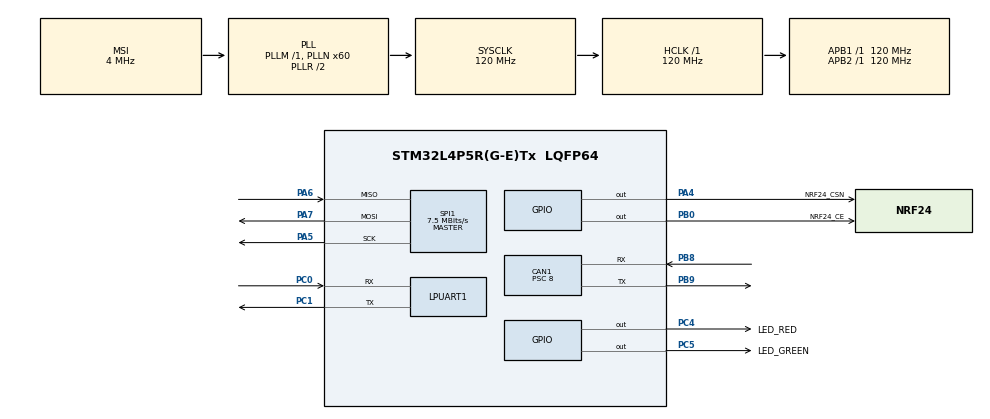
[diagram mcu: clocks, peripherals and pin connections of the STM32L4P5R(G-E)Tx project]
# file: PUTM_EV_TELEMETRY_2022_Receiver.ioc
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CAN1.BS1=CAN_BS1_12TQ
CAN1.BS2=CAN_BS2_2TQ
CAN1.CalculateBaudRate=999999
CAN1.CalculateTimeBit=1000
CAN1.CalculateTimeQuantum=66.66666666666667
CAN1.Mode=CAN_MODE_LOOPBACK
CAN1.Prescaler=8
CAN1.SJW=CAN_SJW_1TQ
Mcu.Family=STM32L4
Mcu.Name=STM32L4P5R(G-E)Tx
Mcu.Package=LQFP64
NVIC.CAN1_RX0_IRQn=true\:1\:0\:true\:false\:true\:true\:true\:true
NVIC.CAN1_RX1_IRQn=true\:0\:0\:false\:false\:true\:true\:true\:true
NVIC.PriorityGroup=NVIC_PRIORITYGROUP_4
NVIC.TIM2_IRQn=true\:0\:0\:false\:false\:true\:true\:true\:true
PA13\ (JTMS/SWDIO).Mode=JTAG_5_pins
PA13\ (JTMS/SWDIO).Signal=SYS_JTMS-SWDIO
PA14\ (JTCK/SWCLK).Mode=JTAG_5_pins
PA14\ (JTCK/SWCLK).Signal=SYS_JTCK-SWCLK
PA15\ (JTDI).Mode=JTAG_5_pins
PA15\ (JTDI).Signal=SYS_JTDI
PA4.GPIO_Label=NRF24_CSN
PA4.Signal=GPIO_Output
PA5.Mode=Full_Duplex_Master
PA5.Signal=SPI1_SCK
PA6.Mode=Full_Duplex_Master
PA6.Signal=SPI1_MISO
PA7.Mode=Full_Duplex_Master
PA7.Signal=SPI1_MOSI
PB0.GPIO_Label=NRF24_CE
PB0.Signal=GPIO_Output
PB3\ (JTDO/TRACESWO).Mode=JTAG_5_pins
PB3\ (JTDO/TRACESWO).Signal=SYS_JTDO-SWO
PB4\ (NJTRST).Mode=JTAG_5_pins
PB4\ (NJTRST).Signal=SYS_JTRST
PB8.Mode=CAN_Activate
PB8.Signal=CAN1_RX
PB9.Mode=CAN_Activate
PB9.Signal=CAN1_TX
PC0.Mode=Asynchronous
PC0.Signal=LPUART1_RX
PC1.Mode=Asynchronous
PC1.Signal=LPUART1_TX
PC14-OSC32_IN\ (PC14).Mode=LSE-External-Oscillator
PC14-OSC32_IN\ (PC14).Signal=RCC_OSC32_IN
PC15-OSC32_OUT\ (PC15).Mode=LSE-External-Oscillator
PC15-OSC32_OUT\ (PC15).Signal=RCC_OSC32_OUT
PC4.GPIO_Label=LED_RED
PC4.Signal=GPIO_Output
PC5.GPIO_Label=LED_GREEN
PC5.Signal=GPIO_Output
PH0-OSC_IN\ (PH0).Mode=HSE-External-Oscillator
PH0-OSC_IN\ (PH0).Signal=RCC_OSC_IN
PH1-OSC_OUT\ (PH1).Mode=HSE-External-Oscillator
PH1-OSC_OUT\ (PH1).Signal=RCC_OSC_OUT
ProjectManager.HeapSize=0x200
ProjectManager.StackSize=0x400
ProjectManager.TargetToolchain=STM32CubeIDE
RCC.AHBFreq_Value=120000000
RCC.APB1Freq_Value=120000000
RCC.APB1TimFreq_Value=120000000
RCC.APB2Freq_Value=120000000
RCC.APB2TimFreq_Value=120000000
RCC.CortexFreq_Value=120000000
RCC.HCLKFreq_Value=120000000
RCC.HSE_VALUE=24576000
RCC.HSI48_VALUE=48000000
RCC.HSI_VALUE=16000000
RCC.MSI_VALUE=4000000
RCC.PLLN=60
RCC.SYSCLKFreq_VALUE=120000000
RCC.SYSCLKSource=RCC_SYSCLKSOURCE_PLLCLK
RCC.VCOOutputFreq_Value=240000000
SPI1.BaudRatePrescaler=SPI_BAUDRATEPRESCALER_16
SPI1.CalculateBaudRate=7.5 MBits/s
SPI1.DataSize=SPI_DATASIZE_8BIT
SPI1.Direction=SPI_DIRECTION_2LINES
SPI1.Mode=SPI_MODE_MASTER
SPI1.VirtualType=VM_MASTER
TIM2.AutoReloadPreload=TIM_AUTORELOAD_PRELOAD_ENABLE
TIM2.Period=100
TIM2.Prescaler=120-1
VP_TIM2_VS_ClockSourceINT.Mode=Internal
board=custom

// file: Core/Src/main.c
/* USER CODE BEGIN Header */
/**
  ******************************************************************************
  * @file           : main.c
  * @brief          : Main program body
  ******************************************************************************
  * @attention
  *
  * Copyright (c) 2022 STMicroelectronics.
  * All rights reserved.
  *
  * This software is licensed under terms that can be found in the LICENSE file
  * in the root directory of this software component.
  * If no LICENSE file comes with this software, it is provided AS-IS.
  *
  ******************************************************************************
  */
/* USER CODE END Header */
#include "main.h"
#include "NRF24L01.h"

 CAN_HandleTypeDef hcan1;

UART_HandleTypeDef hlpuart1;

SPI_HandleTypeDef hspi1;

TIM_HandleTypeDef htim2;

/* USER CODE BEGIN PV */
uint8_t RxAddress[] = {0x00,0xDD,0xCC,0xBB,0xAA};
uint8_t RxData[32];
/* USER CODE END PV */

void SystemClock_Config(void);
static void MX_GPIO_Init(void);
static void MX_CAN1_Init(void);
static void MX_SPI1_Init(void);
static void MX_TIM2_Init(void);
static void MX_LPUART1_UART_Init(void);

int main(void)
{

  /* MCU Configuration--------------------------------------------------------*/

  /* Reset of all peripherals, Initializes the Flash interface and the Systick. */
  HAL_Init();

  /* Configure the system clock */
  SystemClock_Config();

  /* Initialize all configured peripherals */
  MX_GPIO_Init();
  MX_CAN1_Init();
  MX_SPI1_Init();
  MX_TIM2_Init();
  MX_LPUART1_UART_Init();
  /* USER CODE BEGIN 2 */
  NRF24_Init();
  NRF24_RxMode(RxAddress, 10);
  /* USER CODE END 2 */

  /* Infinite loop */
  while (1)
  {

    /* USER CODE BEGIN 3 */
	  if (isDataAvailable(2) == 1)
		  {
			  NRF24_Receive(RxData);
			  //HAL_UART_Transmit(&huart2, RxData, strlen((char *)RxData), 1000);
		  }
  }
  /* USER CODE END 3 */
}

void SystemClock_Config(void)
{
  RCC_OscInitTypeDef RCC_OscInitStruct = {0};
  RCC_ClkInitTypeDef RCC_ClkInitStruct = {0};

  /** Configure the main internal regulator output voltage
  */
  if (HAL_PWREx_ControlVoltageScaling(PWR_REGULATOR_VOLTAGE_SCALE1_BOOST) != HAL_OK)
  {
    Error_Handler();
  }

  /** Initializes the RCC Oscillators according to the specified parameters
  * in the RCC_OscInitTypeDef structure.
  */
  RCC_OscInitStruct.OscillatorType = RCC_OSCILLATORTYPE_MSI;
  RCC_OscInitStruct.MSIState = RCC_MSI_ON;
  RCC_OscInitStruct.MSICalibrationValue = 0;
  RCC_OscInitStruct.MSIClockRange = RCC_MSIRANGE_6;
  RCC_OscInitStruct.PLL.PLLState = RCC_PLL_ON;
  RCC_OscInitStruct.PLL.PLLSource = RCC_PLLSOURCE_MSI;
  RCC_OscInitStruct.PLL.PLLM = 1;
  RCC_OscInitStruct.PLL.PLLN = 60;
  RCC_OscInitStruct.PLL.PLLP = RCC_PLLP_DIV2;
  RCC_OscInitStruct.PLL.PLLQ = RCC_PLLQ_DIV2;
  RCC_OscInitStruct.PLL.PLLR = RCC_PLLR_DIV2;
  if (HAL_RCC_OscConfig(&RCC_OscInitStruct) != HAL_OK)
  {
    Error_Handler();
  }

  /** Initializes the CPU, AHB and APB buses clocks
  */
  RCC_ClkInitStruct.ClockType = RCC_CLOCKTYPE_HCLK|RCC_CLOCKTYPE_SYSCLK
                              |RCC_CLOCKTYPE_PCLK1|RCC_CLOCKTYPE_PCLK2;
  RCC_ClkInitStruct.SYSCLKSource = RCC_SYSCLKSOURCE_PLLCLK;
  RCC_ClkInitStruct.AHBCLKDivider = RCC_SYSCLK_DIV1;
  RCC_ClkInitStruct.APB1CLKDivider = RCC_HCLK_DIV1;
  RCC_ClkInitStruct.APB2CLKDivider = RCC_HCLK_DIV1;

  if (HAL_RCC_ClockConfig(&RCC_ClkInitStruct, FLASH_LATENCY_5) != HAL_OK)
  {
    Error_Handler();
  }
}

static void MX_CAN1_Init(void)
{

  hcan1.Instance = CAN1;
  hcan1.Init.Prescaler = 8;
  hcan1.Init.Mode = CAN_MODE_LOOPBACK;
  hcan1.Init.SyncJumpWidth = CAN_SJW_1TQ;
  hcan1.Init.TimeSeg1 = CAN_BS1_12TQ;
  hcan1.Init.TimeSeg2 = CAN_BS2_2TQ;
  hcan1.Init.TimeTriggeredMode = DISABLE;
  hcan1.Init.AutoBusOff = DISABLE;
  hcan1.Init.AutoWakeUp = DISABLE;
  hcan1.Init.AutoRetransmission = DISABLE;
  hcan1.Init.ReceiveFifoLocked = DISABLE;
  hcan1.Init.TransmitFifoPriority = DISABLE;
  if (HAL_CAN_Init(&hcan1) != HAL_OK)
  {
    Error_Handler();
  }

}

static void MX_LPUART1_UART_Init(void)
{

  hlpuart1.Instance = LPUART1;
  hlpuart1.Init.BaudRate = 209700;
  hlpuart1.Init.WordLength = UART_WORDLENGTH_7B;
  hlpuart1.Init.StopBits = UART_STOPBITS_1;
  hlpuart1.Init.Parity = UART_PARITY_NONE;
  hlpuart1.Init.Mode = UART_MODE_TX_RX;
  hlpuart1.Init.HwFlowCtl = UART_HWCONTROL_NONE;
  hlpuart1.Init.OneBitSampling = UART_ONE_BIT_SAMPLE_DISABLE;
  hlpuart1.Init.ClockPrescaler = UART_PRESCALER_DIV1;
  hlpuart1.AdvancedInit.AdvFeatureInit = UART_ADVFEATURE_NO_INIT;
  hlpuart1.FifoMode = UART_FIFOMODE_DISABLE;
  if (HAL_UART_Init(&hlpuart1) != HAL_OK)
  {
    Error_Handler();
  }
  if (HAL_UARTEx_SetTxFifoThreshold(&hlpuart1, UART_TXFIFO_THRESHOLD_1_8) != HAL_OK)
  {
    Error_Handler();
  }
  if (HAL_UARTEx_SetRxFifoThreshold(&hlpuart1, UART_RXFIFO_THRESHOLD_1_8) != HAL_OK)
  {
    Error_Handler();
  }
  if (HAL_UARTEx_DisableFifoMode(&hlpuart1) != HAL_OK)
  {
    Error_Handler();
  }

}

static void MX_SPI1_Init(void)
{

  /* SPI1 parameter configuration*/
  hspi1.Instance = SPI1;
  hspi1.Init.Mode = SPI_MODE_MASTER;
  hspi1.Init.Direction = SPI_DIRECTION_2LINES;
  hspi1.Init.DataSize = SPI_DATASIZE_8BIT;
  hspi1.Init.CLKPolarity = SPI_POLARITY_LOW;
  hspi1.Init.CLKPhase = SPI_PHASE_1EDGE;
  hspi1.Init.NSS = SPI_NSS_SOFT;
  hspi1.Init.BaudRatePrescaler = SPI_BAUDRATEPRESCALER_16;
  hspi1.Init.FirstBit = SPI_FIRSTBIT_MSB;
  hspi1.Init.TIMode = SPI_TIMODE_DISABLE;
  hspi1.Init.CRCCalculation = SPI_CRCCALCULATION_DISABLE;
  hspi1.Init.CRCPolynomial = 7;
  hspi1.Init.CRCLength = SPI_CRC_LENGTH_DATASIZE;
  hspi1.Init.NSSPMode = SPI_NSS_PULSE_ENABLE;
  if (HAL_SPI_Init(&hspi1) != HAL_OK)
  {
    Error_Handler();
  }

}

static void MX_TIM2_Init(void)
{

  TIM_ClockConfigTypeDef sClockSourceConfig = {0};
  TIM_MasterConfigTypeDef sMasterConfig = {0};

  htim2.Instance = TIM2;
  htim2.Init.Prescaler = 120-1;
  htim2.Init.CounterMode = TIM_COUNTERMODE_UP;
  htim2.Init.Period = 100;
  htim2.Init.ClockDivision = TIM_CLOCKDIVISION_DIV1;
  htim2.Init.AutoReloadPreload = TIM_AUTORELOAD_PRELOAD_ENABLE;
  if (HAL_TIM_Base_Init(&htim2) != HAL_OK)
  {
    Error_Handler();
  }
  sClockSourceConfig.ClockSource = TIM_CLOCKSOURCE_INTERNAL;
  if (HAL_TIM_ConfigClockSource(&htim2, &sClockSourceConfig) != HAL_OK)
  {
    Error_Handler();
  }
  sMasterConfig.MasterOutputTrigger = TIM_TRGO_RESET;
  sMasterConfig.MasterSlaveMode = TIM_MASTERSLAVEMODE_DISABLE;
  if (HAL_TIMEx_MasterConfigSynchronization(&htim2, &sMasterConfig) != HAL_OK)
  {
    Error_Handler();
  }

}

static void MX_GPIO_Init(void)
{
  GPIO_InitTypeDef GPIO_InitStruct = {0};

  /* GPIO Ports Clock Enable */
  __HAL_RCC_GPIOC_CLK_ENABLE();
  __HAL_RCC_GPIOH_CLK_ENABLE();
  __HAL_RCC_GPIOA_CLK_ENABLE();
  __HAL_RCC_GPIOB_CLK_ENABLE();

  /*Configure GPIO pin Output Level */
  HAL_GPIO_WritePin(NRF24_CSN_GPIO_Port, NRF24_CSN_Pin, GPIO_PIN_RESET);

  /*Configure GPIO pin Output Level */
  HAL_GPIO_WritePin(GPIOC, LED_RED_Pin|LED_GREEN_Pin, GPIO_PIN_RESET);

  /*Configure GPIO pin Output Level */
  HAL_GPIO_WritePin(NRF24_CE_GPIO_Port, NRF24_CE_Pin, GPIO_PIN_RESET);

  /*Configure GPIO pin : NRF24_CSN_Pin */
  GPIO_InitStruct.Pin = NRF24_CSN_Pin;
  GPIO_InitStruct.Mode = GPIO_MODE_OUTPUT_PP;
  GPIO_InitStruct.Pull = GPIO_NOPULL;
  GPIO_InitStruct.Speed = GPIO_SPEED_FREQ_LOW;
  HAL_GPIO_Init(NRF24_CSN_GPIO_Port, &GPIO_InitStruct);

  /*Configure GPIO pins : LED_RED_Pin LED_GREEN_Pin */
  GPIO_InitStruct.Pin = LED_RED_Pin|LED_GREEN_Pin;
  GPIO_InitStruct.Mode = GPIO_MODE_OUTPUT_PP;
  GPIO_InitStruct.Pull = GPIO_NOPULL;
  GPIO_InitStruct.Speed = GPIO_SPEED_FREQ_LOW;
  HAL_GPIO_Init(GPIOC, &GPIO_InitStruct);

  /*Configure GPIO pin : NRF24_CE_Pin */
  GPIO_InitStruct.Pin = NRF24_CE_Pin;
  GPIO_InitStruct.Mode = GPIO_MODE_OUTPUT_PP;
  GPIO_InitStruct.Pull = GPIO_NOPULL;
  GPIO_InitStruct.Speed = GPIO_SPEED_FREQ_LOW;
  HAL_GPIO_Init(NRF24_CE_GPIO_Port, &GPIO_InitStruct);

}

void Error_Handler(void)
{
  __disable_irq();
  while (1)
  {
  }
}
